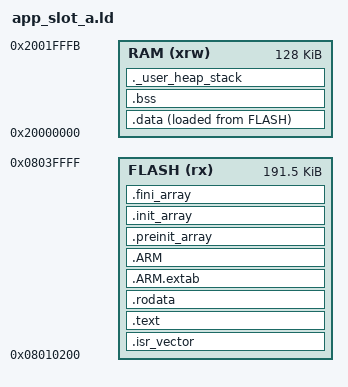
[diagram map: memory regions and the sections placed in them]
ENTRY(Reset_Handler)

MEMORY
{
    RAM   (xrw) : ORIGIN = 0x20000000, LENGTH = 128K - 4  /* top word reserved for DFU trigger flag */
    FLASH (rx)  : ORIGIN = 0x08010200, LENGTH = 192K - 512  /* Slot A, after 512-byte image header */
}

/* Flash region symbols, access in C/C++ via the address of the symbol: &_slot_a_base */
_metadata_base = 0x0800C000;
_slot_a_base   = 0x08010000;
_slot_a_end    = 0x08040000;
_slot_b_base   = 0x08040000;
_slot_b_end    = 0x08080000;

_estack = ORIGIN(RAM) + LENGTH(RAM);
_Min_Heap_Size  = 0x200;
_Min_Stack_Size = 0x400;

SECTIONS
{
  .isr_vector :
  {
    . = ALIGN(4);
    KEEP(*(.isr_vector))
    . = ALIGN(4);
  } >FLASH

  .text :
  {
    . = ALIGN(4);
    *(.text)
    *(.text*)
    *(.glue_7)
    *(.glue_7t)
    KEEP (*(.init))
    KEEP (*(.fini))
    . = ALIGN(4);
    _etext = .;
  } >FLASH

  .rodata :
  {
    . = ALIGN(4);
    *(.rodata)
    *(.rodata*)
    . = ALIGN(4);
  } >FLASH

  .ARM.extab (READONLY) : { *(.ARM.extab* .gnu.linkonce.armextab.*) } >FLASH
  .ARM (READONLY)       : { __exidx_start = .; *(.ARM.exidx*) __exidx_end = .; } >FLASH

  .preinit_array (READONLY) :
  {
    PROVIDE_HIDDEN (__preinit_array_start = .);
    KEEP (*(.preinit_array*))
    PROVIDE_HIDDEN (__preinit_array_end = .);
  } >FLASH

  .init_array (READONLY) :
  {
    PROVIDE_HIDDEN (__init_array_start = .);
    KEEP (*(SORT(.init_array.*)))
    KEEP (*(.init_array*))
    PROVIDE_HIDDEN (__init_array_end = .);
  } >FLASH

  .fini_array (READONLY) :
  {
    PROVIDE_HIDDEN (__fini_array_start = .);
    KEEP (*(SORT(.fini_array.*)))
    KEEP (*(.fini_array*))
    PROVIDE_HIDDEN (__fini_array_end = .);
  } >FLASH

  _sidata = LOADADDR(.data);

  .data :
  {
    . = ALIGN(4);
    _sdata = .;
    *(.data)
    *(.data*)
    *(.RamFunc)
    *(.RamFunc*)
    . = ALIGN(4);
    _edata = .;
  } >RAM AT> FLASH

  .bss (NOLOAD) :
  {
    . = ALIGN(4);
    _sbss = .;
    *(.bss)
    *(.bss*)
    *(COMMON)
    . = ALIGN(4);
    _ebss = .;
  } >RAM

  ._user_heap_stack (NOLOAD) :
  {
    . = ALIGN(8);
    PROVIDE (end  = .);
    PROVIDE (_end = .);
    . = . + _Min_Heap_Size;
    . = . + _Min_Stack_Size;
    . = ALIGN(8);
  } >RAM
}
